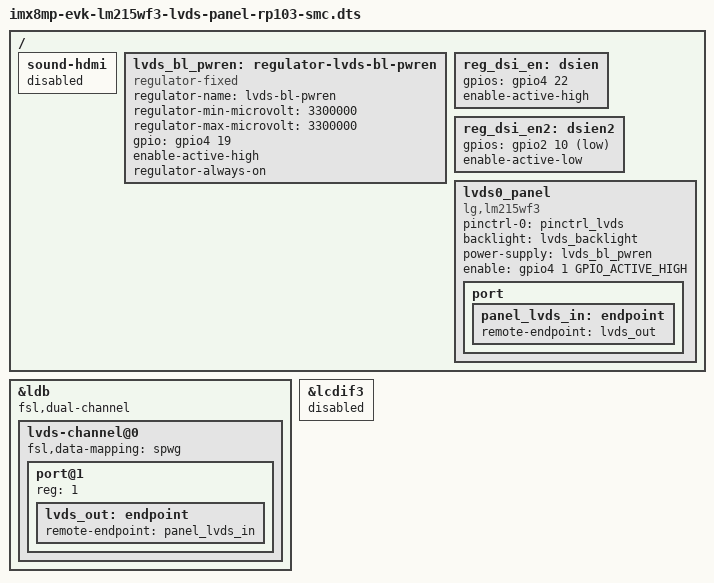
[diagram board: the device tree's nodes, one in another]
#include "imx8mp-evk-rp103-smc.dts"

/ {
	sound-hdmi {
		status = "disabled";
	};
	 lvds_bl_pwren: regulator-lvds-bl-pwren {
		compatible = "regulator-fixed";
		regulator-name = "lvds-bl-pwren";
		regulator-min-microvolt = <3300000>;
		regulator-max-microvolt = <3300000>;
		gpio = <&gpio4 19 GPIO_ACTIVE_HIGH>;
		enable-active-high;
		regulator-always-on;
	};

	reg_dsi_en: dsien {
		gpios = <&gpio4 22 GPIO_ACTIVE_HIGH>;
		enable-active-high;
	};

	reg_dsi_en2: dsien2 {
		gpios = <&gpio2 10 GPIO_ACTIVE_LOW>;
		enable-active-low;
	};

	lvds0_panel {
		compatible = "lg,lm215wf3";
		pinctrl-names = "default";
		pinctrl-0 = <&pinctrl_lvds>;
		backlight = <&lvds_backlight>;
		power-supply = <&lvds_bl_pwren>;
        enable = <&gpio4 1 GPIO_ACTIVE_HIGH >;
		port {
			panel_lvds_in: endpoint {
				remote-endpoint = <&lvds_out>;
			};
		};
	};
};
/delete-node/ &lvds_bridge;
/delete-node/ &adv_bridge;
/delete-node/ &dsim_to_adv7535;

&ldb {
	fsl,dual-channel;
	lvds-channel@0 {
		fsl,data-mapping = "spwg";

		/delete-node/ port@1;

		port@1 {
			reg = <1>;

			lvds_out: endpoint {
				remote-endpoint = <&panel_lvds_in>;
			};
		};
	};
};

&lcdif3 {
	status = "disabled";
};
